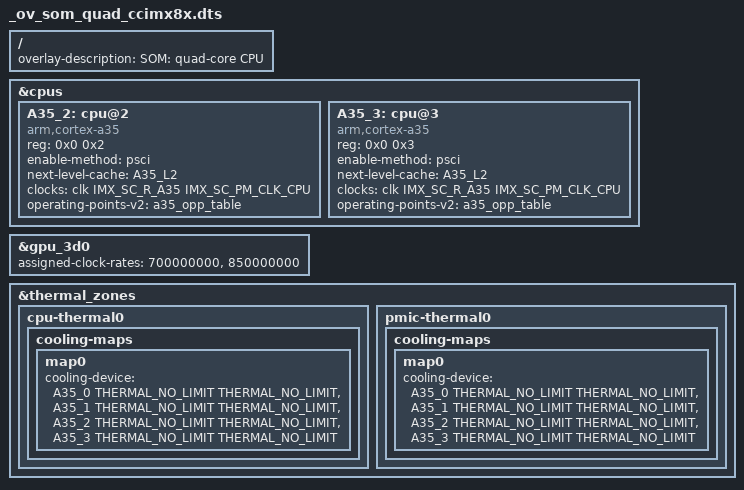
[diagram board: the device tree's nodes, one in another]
/*
 * Copyright 2020 Digi International Inc.
 *
 * Permission to use, copy, modify, and/or distribute this software for any
 * purpose with or without fee is hereby granted, provided that the above
 * copyright notice and this permission notice appear in all copies.
 * THE SOFTWARE IS PROVIDED "AS IS" AND THE AUTHOR DISCLAIMS ALL WARRANTIES
 * WITH REGARD TO THIS SOFTWARE INCLUDING ALL IMPLIED WARRANTIES OF
 * MERCHANTABILITY AND FITNESS. IN NO EVENT SHALL THE AUTHOR BE LIABLE FOR
 * ANY SPECIAL, DIRECT, INDIRECT, OR CONSEQUENTIAL DAMAGES OR ANY DAMAGES
 * WHATSOEVER RESULTING FROM LOSS OF USE, DATA OR PROFITS, WHETHER IN AN
 * ACTION OF CONTRACT, NEGLIGENCE OR OTHER TORTIOUS ACTION, ARISING OUT OF
 * OR IN CONNECTION WITH THE USE OR PERFORMANCE OF THIS SOFTWARE.
 */

#include <dt-bindings/firmware/imx/rsrc.h>
#include <dt-bindings/thermal/thermal.h>

/dts-v1/;
/plugin/;

/ {
	fragment@0 {
		target-path = "/";
		__overlay__ {
			overlay-description = "SOM: quad-core CPU";
		};
	};

	/* Add the 2 additional Cortex-A35 cores */
	fragment@1 {
		target = <&cpus>;
		__overlay__ {
			#address-cells = <2>;
			#size-cells = <0>;

			A35_2: cpu@2 {
				device_type = "cpu";
				compatible = "arm,cortex-a35";
				reg = <0x0 0x2>;
				enable-method = "psci";
				next-level-cache = <&A35_L2>;
				clocks = <&clk IMX_SC_R_A35 IMX_SC_PM_CLK_CPU>;
				operating-points-v2 = <&a35_opp_table>;
				#cooling-cells = <2>;
			};

			A35_3: cpu@3 {
				device_type = "cpu";
				compatible = "arm,cortex-a35";
				reg = <0x0 0x3>;
				enable-method = "psci";
				next-level-cache = <&A35_L2>;
				clocks = <&clk IMX_SC_R_A35 IMX_SC_PM_CLK_CPU>;
				operating-points-v2 = <&a35_opp_table>;
				#cooling-cells = <2>;
			};
		};
	};

	/* Increase gpu_3d0's assigned clock rates */
	fragment@2 {
		target = <&gpu_3d0>;
		__overlay__ {
			assigned-clock-rates = <700000000>, <850000000>;
		};
	};

	/* Add the 2 additional Cortex-A35 cores to the CPU and PMIC cooling maps */
	fragment@3 {
		target = <&thermal_zones>;
		__overlay__ {
			cpu-thermal0 {
				cooling-maps {
					map0 {
						cooling-device =
						<&A35_0 THERMAL_NO_LIMIT THERMAL_NO_LIMIT>,
						<&A35_1 THERMAL_NO_LIMIT THERMAL_NO_LIMIT>,
						<&A35_2 THERMAL_NO_LIMIT THERMAL_NO_LIMIT>,
						<&A35_3 THERMAL_NO_LIMIT THERMAL_NO_LIMIT>;
					};
				};
			};

			pmic-thermal0 {
				cooling-maps {
					map0 {
						cooling-device =
						<&A35_0 THERMAL_NO_LIMIT THERMAL_NO_LIMIT>,
						<&A35_1 THERMAL_NO_LIMIT THERMAL_NO_LIMIT>,
						<&A35_2 THERMAL_NO_LIMIT THERMAL_NO_LIMIT>,
						<&A35_3 THERMAL_NO_LIMIT THERMAL_NO_LIMIT>;
					};
				};
			};
		};
	};
};
